# ADuCM355 register map
Vendor: Analog Devices; Series: ADuCM355; File version: 1p0
CPU: CM3 r0p1, little endian, no MPU, no FPU, 3 interrupt priority bits
Registers are 32-bit, read-write, reset 0x0 unless marked. A register's access mark holds for its fields unless they carry their own. Offsets are from the block's base; [hi:lo] are bit positions; {n}, {i} and the like mark numbered series.

## RTC0 — Real-Time Clock
Base 0x40001000
Same registers: RTC1 0x40001400
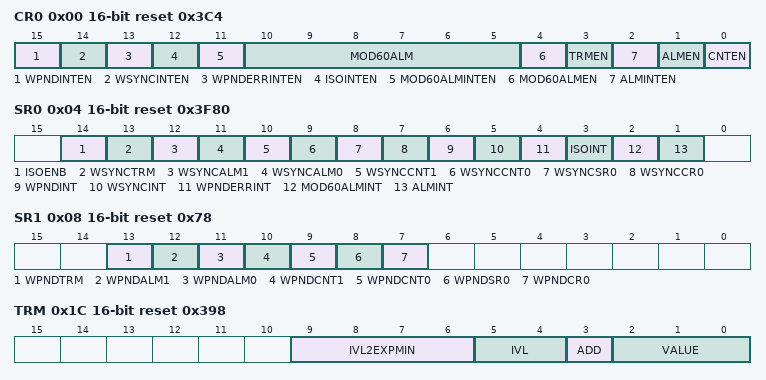
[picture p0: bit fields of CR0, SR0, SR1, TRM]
0x00 CR0 16-bit reset 0x3C4 — RTC Control 0
  [15] WPNDINTEN — Enable Write Pending sourced interrupts to the CPU
  [14] WSYNCINTEN — Enable Write synchronization sourced interrupts to the CPU
  [13] WPNDERRINTEN — Enable Write pending error sourced interrupts to the CPU when an RTC register-write pending error occurs
  [12] ISOINTEN — Enable RTC power-domain isolation sourced interrupts to the CPU when isolation of the RTC power domain is activated and subsequently de-activated
  [11] MOD60ALMINTEN — Enable periodic Modulo-60 RTC alarm sourced interrupts to the CPU
  [10:5] MOD60ALM — Periodic, modulo-60 alarm time in prescaled RTC time units beyond a modulo-60 boundary
    30=Example_1_Thirty_time_units_decimal (Example of setting a modulo-60 periodic interrupt from the RTC to be issued to the CPU at 30 time units past a modulo-60 boundary.); 55=Example_2_FiftyFive_time_units_decimal (Example of setting a modulo-60 periodic interrupt from the RTC to be issued to the CPU at 55 time units past a modulo-60 boundary.)
  [4] MOD60ALMEN — Enable RTC modulo-60 counting of time past a modulo-60 boundary
  [3] TRMEN — Enable RTC digital trimming
  [2] ALMINTEN — Enable sourced alarm interrupts to the CPU
  [1] ALMEN — Enable the RTC alarm (absolute) operation
  [0] CNTEN — Global enable for the RTC
0x04 SR0 16-bit reset 0x3F80 — RTC Status 0
  [14] ISOENB ro — Visibility status of 32 kHz sourced registers, taking account of power-domain isolation
  [13] WSYNCTRM ro — Synchronization status of posted writes to RTC Trim Register
  [12] WSYNCALM1 ro — Synchronization status of posted writes to RTC Alarm 1 Register
  [11] WSYNCALM0 ro — Synchronization status of posted writes to RTC Alarm 0 Register
  [10] WSYNCCNT1 ro — Synchronization status of posted writes to RTC Count 1 Register
  [9] WSYNCCNT0 ro — Synchronization status of posted writes to RTC Count 0 Register
  [8] WSYNCSR0 ro — Synchronization status of posted clearances to interrupt sources in RTC Status 0 Register
  [7] WSYNCCR0 ro — Synchronization status of posted writes to RTC Control 0 Register
  [6] WPNDINT — Write pending interrupt
  [5] WSYNCINT — Write synchronization interrupt
  [4] WPNDERRINT — Write pending error interrupt source
  [3] ISOINT — RTC power-domain isolation interrupt source
  [2] MOD60ALMINT — Modulo-60 RTC alarm interrupt source
  [1] ALMINT — Alarm interrupt source
0x08 SR1 16-bit reset 0x78 — RTC Status 1
  [13] WPNDTRM ro — Pending status of posted writes to RTC Trim Register
  [12] WPNDALM1 ro — Pending status of posted writes to RTC ALARM 1 Register
  [11] WPNDALM0 ro — Pending status of posted writes to RTC ALARM 0 Register
  [10] WPNDCNT1 ro — Pending status of posted writes to RTC Count 1 Register
  [9] WPNDCNT0 ro — Pending status of posted writes to RTC Count 0 Register
  [8] WPNDSR0 ro — Pending status of posted clearances of interrupt sources in RTC Status 0 Register
  [7] WPNDCR0 ro — Pending status of posted writes to RTC Control 0 Register
0x0C CNT0 16-bit — RTC Count 0
  [15:0] VALUE range 0x00000000..0x0000FFFF — Lower 16 prescaled (non-fractional) bits of the RTC real-time count
0x10 CNT1 16-bit — RTC Count 1
  [15:0] VALUE range 0x00000000..0x0000FFFF — Upper 16 prescaled (non-fractional) bits of the RTC real-time count
0x14 ALM0 16-bit reset 0xFFFF — RTC Alarm 0
  [15:0] VALUE range 0x00000000..0x0000FFFF — Lower 16 prescaled (that is, non-fractional) bits of the RTC alarm target time
0x18 ALM1 16-bit reset 0xFFFF — RTC Alarm 1
  [15:0] VALUE range 0x00000000..0x0000FFFF — Upper 16 prescaled (non-fractional) bits of the RTC alarm target time
0x1C TRM 16-bit reset 0x398 — RTC Trim
  [9:6] IVL2EXPMIN range 0x00000000..0x0000000F — Minimum power-of-two interval of prescaled RTC time units, which RTC Trim Register can select
  [5:4] IVL — Trim interval in prescaled RTC time units
  [3] ADD — Trim Polarity
  [2:0] VALUE — Trim value in prescaled RTC time units to be added or subtracted from the RTC count at the end of a periodic interval selected by RTC Trim Register
0x20 GWY 16-bit — RTC Gateway
  [15:0] SWKEY wo range 0x00000000..0x0000FFFF — Software-keyed command issued by the CPU
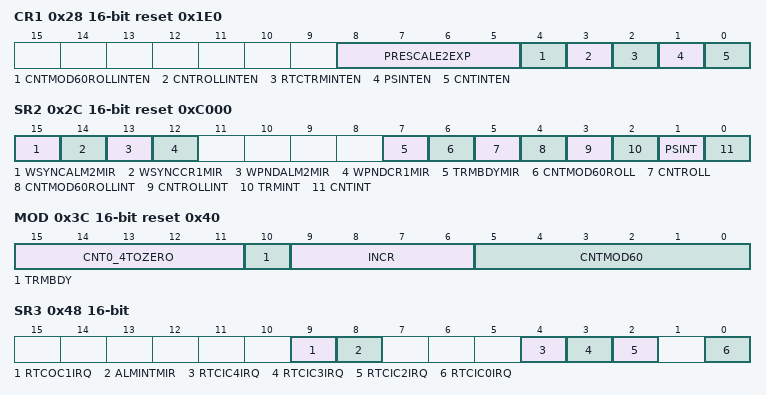
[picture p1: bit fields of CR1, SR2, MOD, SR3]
0x28 CR1 16-bit reset 0x1E0 — RTC Control 1
  [8:5] PRESCALE2EXP — Prescale power of 2 division factor for the RTC base clock
  [4] CNTMOD60ROLLINTEN — Enable for the RTC modulo-60 count roll-over interrupt source in RTC Status 2 Register
  [3] CNTROLLINTEN — Enable for the RTC count roll-over interrupt source in RTC Status 2 Register
  [2] RTCTRMINTEN — Enable for the RTC Trim interrupt source
  [1] PSINTEN — Enable for the prescaled, modulo-1 interrupt source
  [0] CNTINTEN — Enable for the RTC count interrupt source
0x2C SR2 16-bit reset 0xC000 — RTC Status 2
  [15] WSYNCALM2MIR ro — Synchronization status of posted writes to RTC Alarm 2 Register
  [14] WSYNCCR1MIR ro — Synchronization status of posted writes to RTC Control 1 Register
  [13] WPNDALM2MIR ro — Pending status of posted writes to RTC Alarm 2 Register
  [12] WPNDCR1MIR ro — Pending status of posted writes to RTC Control 1 Register
  [7] TRMBDYMIR ro — Mirror of the RTCTRMBDY field of RTC Modulo Register
  [6] CNTMOD60ROLL ro — RTC count modulo-60 roll-over
  [5] CNTROLL ro — RTC count roll-over
  [4] CNTMOD60ROLLINT — RTC modulo-60 count roll-over interrupt source
  [3] CNTROLLINT — RTC count roll-over interrupt source
  [2] TRMINT — RTC Trim interrupt source
  [1] PSINT — RTC prescaled, modulo-1 boundary interrupt source
  [0] CNTINT — RTC count interrupt source
0x30 SNAP0 16-bit — RTC Snapshot 0
  [15:0] VALUE ro — Constituent part of the 47-bit RTC Input Capture Channel 0, containing a sticky snapshot of RTC Count 0 Register
0x34 SNAP1 16-bit — RTC Snapshot 1
  [15:0] VALUE ro — Constituent part of the 47-bit RTC Input Capture Channel 0, containing a sticky snapshot of RTC Count 1 Register
0x38 SNAP2 16-bit — RTC Snapshot 2
  [14:0] VALUE ro — Constituent part of the 47-bit RTC Input Capture Channel 0, containing a sticky snapshot of RTC Count 2 Register
0x3C MOD 16-bit reset 0x40 — RTC Modulo
  [15:11] CNT0_4TOZERO ro — Mirror of RTC Count 0 Register [4:0]
  [10] TRMBDY ro — Trim boundary indicator that the most recent RTC count increment has coincided with trimming of the count value
  [9:6] INCR ro — Most recent increment value added to the RTC Count in RTC Count 1 and RTC Count 0 Registers
  [5:0] CNTMOD60 ro — Modulo-60 value of prescaled RTC Count 1 and RTC Count 0 Registers
0x40 CNT2 16-bit — RTC Count 2
  [14:0] VALUE ro — Fractional bits of the RTC real-time count
0x44 ALM2 16-bit — RTC Alarm 2
  [14:0] VALUE range 0x00000000..0x00007FFF — Fractional (non-prescaled) bits of the RTC alarm target time
0x48 SR3 16-bit — RTC Status 3
  [9] RTCOC1IRQ — Sticky Interrupt Source for Output Compare Channel 1
  [8] ALMINTMIR ro — Read-only mirror of the ALMINT interrupt source in RTC Status 0 Register, acting as RTCOC0IRQ
  [4] RTCIC4IRQ — Sticky Interrupt Source for the RTC Input Capture Channel 4
  [3] RTCIC3IRQ — Sticky Interrupt Source for the RTC Input Capture Channel 3
  [2] RTCIC2IRQ — Sticky Interrupt Source for the RTC Input Capture Channel 2
  [0] RTCIC0IRQ — Sticky Interrupt Source for the RTC Input Capture Channel 0
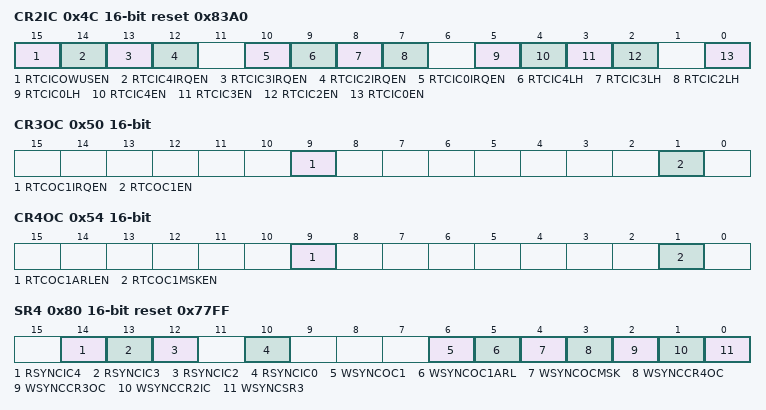
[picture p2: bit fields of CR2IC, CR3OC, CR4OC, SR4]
0x4C CR2IC 16-bit reset 0x83A0 — RTC Control 2 for Configuring Input Capture Channels
  [15] RTCICOWUSEN — Enable Overwrite of Unread Snapshots for all RTC Input Capture Channels
  [14] RTCIC4IRQEN — Interrupt Enable for the RTC Input Capture Channel 4
  [13] RTCIC3IRQEN — Interrupt Enable for the RTC Input Capture Channel 3
  [12] RTCIC2IRQEN — Interrupt Enable for the RTC Input Capture Channel 2
  [10] RTCIC0IRQEN — Interrupt Enable for the RTC Input Capture Channel 0
  [9] RTCIC4LH — Polarity of the active-going capture edge for the RTC Input Capture Channel 4
  [8] RTCIC3LH — Polarity of the active-going capture edge for the RTC Input Capture Channel 3
  [7] RTCIC2LH — Polarity of the active-going capture edge for the RTC Input Capture Channel 2
  [5] RTCIC0LH — Polarity of the active-going capture edge for the RTC Input Capture Channel 0
  [4] RTCIC4EN — Enable for the RTC Input Capture Channel 4
  [3] RTCIC3EN — Enable for the RTC Input Capture Channel 3
  [2] RTCIC2EN — Enable for the RTC Input Capture Channel 2
  [0] RTCIC0EN — Enable for the RTC Input Capture Channel 0
0x50 CR3OC 16-bit — RTC Control 3 for Configuring Output Compare Channel
  [9] RTCOC1IRQEN — Interrupt Enable for Output Compare Channel 1
  [1] RTCOC1EN — Enable for Output Compare Channel 1
0x54 CR4OC 16-bit — RTC Control 4 for Configuring Output Compare Channel
  [9] RTCOC1ARLEN — Enable for auto-reloading when output compare match occurs
  [1] RTCOC1MSKEN — Enable for thermometer-code masking of the Output Compare 1 Channel
    0=EN000 (Do not apply a mask to the 16-bit Output Compare channel OC1.); 1=EN001 (Apply a thermometer-decoded mask to the 16-bit Output Compare channel OC1 provided that channel is enabled via CR3OC:RTCOC1EN)
0x58 OCMSK 16-bit — RTC Masks for Output Compare Channel
  [15:0] RTCOCMSK range 0x00000000..0x0000FFFF — Concatenation of thermometer-encoded masks for the 16-bit output compare channels
0x5C OC1ARL 16-bit — RTC Auto-Reload for Output Compare Channel 1
  [15:0] RTCOC1ARL range 0x00000000..0x0000FFFF — Auto-reload value when output compare match occurs
{0x5C+4i} IC{i} 16-bit (i=2..4) — RTC Input Capture Channel {i}
  [15:0] RTCIC{i} ro
0x70 OC1 16-bit reset 0x8000 — RTC Output Compare Channel 1
  [15:0] RTCOC1 range 0x00000000..0x0000FFFF — RTC Output Compare 1 Channel. Scheduled alarm target time with optional auto-reload
0x80 SR4 16-bit reset 0x77FF — RTC Status 4
  [14] RSYNCIC4 ro — Synchronization status of posted reads of RTC Input Channel 4
  [13] RSYNCIC3 ro — Synchronization status of posted reads of RTC Input Channel 3
  [12] RSYNCIC2 ro — Synchronization status of posted reads of RTC Input Channel 2
  [10] RSYNCIC0 ro — Synchronization status of posted reads of RTC Input Channel 0
  [6] WSYNCOC1 ro — Synchronization status of posted writes to RTC Output Compare Channel 1 Register
  [5] WSYNCOC1ARL ro — Synchronization status of posted writes to RTC Auto-Reload for Output Compare Channel 1 Register
  [4] WSYNCOCMSK ro — Synchronization status of posted writes to RTC Masks for Output Compare Channel Register
  [3] WSYNCCR4OC ro — Synchronization status of posted writes to RTC Control 4 for Configuring Output Compare Channel Register
  [2] WSYNCCR3OC ro — Synchronization status of posted writes to RTC Control 3 for Configuring Output Compare Channel Register
  [1] WSYNCCR2IC ro — Synchronization status of posted writes to RTC Control 2 for Configuring Input Capture Channels Register
  [0] WSYNCSR3 ro — Synchronization status of posted clearances to interrupt sources in RTC Status 3 Register
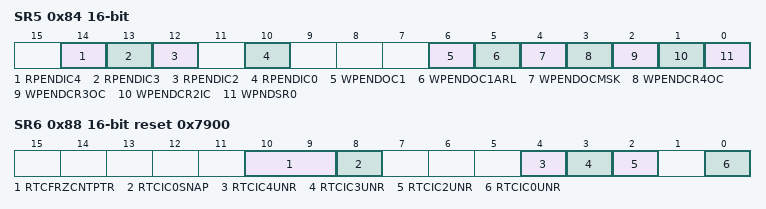
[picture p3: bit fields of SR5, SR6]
0x84 SR5 16-bit — RTC Status 5
  [14] RPENDIC4 ro — Pending status of posted reads of RTC Input Channel 4
  [13] RPENDIC3 ro — Pending status of posted reads of RTC Input Channel 3
  [12] RPENDIC2 ro — Pending status of posted reads of RTC Input Channel 2
  [10] RPENDIC0 ro — Pending status of posted reads of RTC Input Channel 0
  [6] WPENDOC1 ro — Pending status of posted writes to Output Compare Channel 1
  [5] WPENDOC1ARL ro — Pending status of posted writes to RTC Auto-Reload for Output Compare Channel 1 Register
  [4] WPENDOCMSK ro — Pending status of posted writes to RTC Masks for Output Compare Channel Register
  [3] WPENDCR4OC ro — Pending status of posted writes to RTC Control 4 for Configuring Output Compare Channel Register
  [2] WPENDCR3OC ro — Pending status of posted writes to RTC Control 3 for Configuring Output Compare Channel Register
  [1] WPENDCR2IC ro — Pending status of posted writes to RTC Control 2 for Configuring Input Capture Channels Register
  [0] WPNDSR0 ro — Pending status of posted clearances of interrupt sources in RTC Status 3 Register
0x88 SR6 16-bit reset 0x7900 — RTC Status 6
  [10:9] RTCFRZCNTPTR ro — Pointer for the triple-read sequence of the RTC Freeze Count MMR
  [8] RTCIC0SNAP ro — Confirmation that RTC Snapshot 0, 1, 2 registers reflect the value of RTC Input Capture Channel 0
  [4] RTCIC4UNR ro — Sticky unread status of the RTC Input Capture Channel 4
  [3] RTCIC3UNR ro — Sticky unread status of the RTC Input Capture Channel 3
  [2] RTCIC2UNR ro — Sticky unread status of the RTC Input Capture Channel 2
  [0] RTCIC0UNR ro — Sticky unread status of the RTC Input Capture Channel 0
0x8C OC1TGT 16-bit reset 0x8000 — RTC Output Compare Channel 1 Target
  [15:0] RTCOC1TGT ro — Current, cumulative target time for Output Compare Channel 1, taking account of any auto-reloading
0x90 FRZCNT 16-bit — RTC Freeze Count
  [15:0] RTCFRZCNT ro
